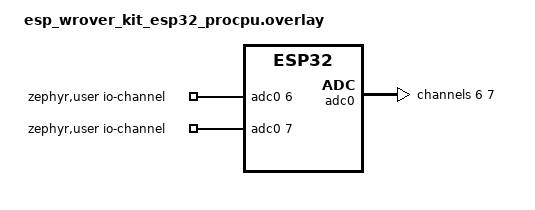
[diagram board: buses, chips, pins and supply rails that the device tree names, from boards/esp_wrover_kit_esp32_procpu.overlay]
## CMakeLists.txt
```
# SPDX-License-Identifier: Apache-2.0

cmake_minimum_required(VERSION 3.20.0)
find_package(Zephyr REQUIRED HINTS $ENV{ZEPHYR_BASE})
project(soil-monitor)

target_sources(app PRIVATE
    src/main.c
    src/wifi.c
)
```

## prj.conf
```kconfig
# ========================================
# CONFIGURAÇÕES DE HARDWARE E CONSOLE
# ========================================
CONFIG_GPIO=y
CONFIG_ADC=y
CONFIG_SERIAL=y
CONFIG_CONSOLE=y
CONFIG_UART_CONSOLE=y
CONFIG_PRINTK=y

# ========================================
# ZBUS (Barramento de Mensagens)
# ========================================
CONFIG_ZBUS=y

# ========================================
# REDE, WI-FI E NET_MGMT
# ========================================
CONFIG_NETWORKING=y
CONFIG_NET_IPV4=y
CONFIG_NET_TCP=y
CONFIG_NET_UDP=y
CONFIG_NET_SOCKETS=y
CONFIG_NET_MGMT=y
CONFIG_NET_MGMT_EVENT=y
CONFIG_WIFI=y
CONFIG_WIFI_ESP32=y
CONFIG_NET_L2_WIFI_MGMT=y
CONFIG_NET_DHCPV4=y

# ========================================
# ATIVAR A SHELL DO ZEPHYR (Novidade aqui)
# ========================================
CONFIG_SHELL=y
CONFIG_SHELL_STACK_SIZE=4096

# ========================================
# CONFIGURAÇÕES DE MEMÓRIA
# ========================================
CONFIG_MAIN_STACK_SIZE=4096
CONFIG_HEAP_MEM_POOL_SIZE=8192
```

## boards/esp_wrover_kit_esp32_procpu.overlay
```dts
/* SPDX-License-Identifier: Apache-2.0 */

/ {
	aliases {
		led0 = &red_led;
		led1 = &green_led;
		led2 = &blue_led;
	};

	zephyr,user {
		/* CORREÇÃO: Mapeia os canais indexados 0 e 1, respectivamente */
		io-channels = <&adc0 6>, <&adc0 7>;
	};
};

&adc0 {
	status = "okay";
	#address-cells = <1>;
	#size-cells = <0>;

	channel@6 {
		reg = <6>;
		zephyr,gain = "ADC_GAIN_1_4";
		zephyr,reference = "ADC_REF_INTERNAL";
		zephyr,acquisition-time = <ADC_ACQ_TIME_DEFAULT>;
		zephyr,resolution = <12>;
	};

	/* NOVO: Configuração para o segundo potenciômetro (GPIO 35) */
	channel@7 {
		reg = <7>;
		zephyr,gain = "ADC_GAIN_1_4";
		zephyr,reference = "ADC_REF_INTERNAL";
		zephyr,acquisition-time = <ADC_ACQ_TIME_DEFAULT>;
		zephyr,resolution = <12>;
	};
};
```

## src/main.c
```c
#include <zephyr/kernel.h>
#include <zephyr/drivers/gpio.h>
#include <zephyr/drivers/adc.h>
#include <zephyr/sys/printk.h>
#include <zephyr/zbus/zbus.h>
#include <zephyr/net/socket.h> /* Fornece as estruturas zsock_ e AF_INET */

#include "wifi.h"

/* ====================================================================
 * NOVO: Variável global para armazenar o estado da irrigação
 * ==================================================================== */
static volatile bool esta_irrigando = false;


/* NOVO: Guarda a última leitura do Pot1. Inicializado em 2000 (Úmido) 
   para segurança, evitando ligar o LED antes da primeira leitura do ADC */
   
static volatile uint16_t ultima_umidade = 2000; 


/* =========================================
 * MODIFICAÇÃO: Estrutura agora leva o estado
 * ========================================= */
struct pots_data {
    uint16_t pot1;
    uint16_t pot2;
    bool irrigando; /* NOVO CAMPO */
};

/* =========================================
 * DEFINIÇÃO DO ZBUS
 * ========================================= */
/* Inicializa o canal limpando também o novo campo booleano */
ZBUS_CHAN_DEFINE(adc_data_chan, struct pots_data, NULL, NULL, ZBUS_OBSERVERS_EMPTY, ZBUS_MSG_INIT(.pot1 = 0, .pot2 = 0, .irrigando = false));

ZBUS_SUBSCRIBER_DEFINE(http_subscriber, 4);
ZBUS_CHAN_ADD_OBS(adc_data_chan, http_subscriber, 3);

/* =========================================
 * CONFIGURAÇÕES DO SERVIDOR HTTP
 * ========================================= */
#define HTTP_SERVER_IP "192.168.0.5"
#define HTTP_SERVER_PORT 8080

/* =========================================
 * THREAD DO LED (Atualiza a variável global)
 * ========================================= */
#define SLEEP_TIME_ON_MS   10000
#define SLEEP_TIME_OFF_MS  10000
#define LED0_NODE DT_ALIAS(led0)
static const struct gpio_dt_spec led = GPIO_DT_SPEC_GET(LED0_NODE, gpios);

void led_thread_function(void) {
    if (!gpio_is_ready_dt(&led)) return;
    
    gpio_pin_configure_dt(&led, GPIO_OUTPUT_INACTIVE);

    while (1) {

        if (ultima_umidade < 1600){

            
            gpio_pin_set_dt(&led, 1);
            esta_irrigando = true;
            k_msleep(SLEEP_TIME_ON_MS);


            gpio_pin_set_dt(&led, 0);
            esta_irrigando = false;
            k_msleep(SLEEP_TIME_OFF_MS);

        }else{

            gpio_pin_set_dt(&led, 0);
            esta_irrigando = false;
            k_msleep(SLEEP_TIME_OFF_MS);
        }


    }

        
        


}
K_THREAD_DEFINE(led_thread_id, 512, led_thread_function, NULL, NULL, NULL, 7, 0, 0);



/* =========================================
 * THREAD DO HTTP (Envia o estado no JSON)
 * ========================================= */
static void send_http_post(struct pots_data data) {
    int sock;
    struct sockaddr_in server_addr;
    char payload[160]; /* Aumentado ligeiramente para a nova chave */
    char request[350];

    sock = zsock_socket(AF_INET, SOCK_STREAM, IPPROTO_TCP);
    if (sock < 0) return;

    server_addr.sin_family = AF_INET;
    server_addr.sin_port = htons(HTTP_SERVER_PORT);
    zsock_inet_pton(AF_INET, HTTP_SERVER_IP, &server_addr.sin_addr);

    if (zsock_connect(sock, (struct sockaddr *)&server_addr, sizeof(server_addr)) < 0) {
        printk("[HTTP] Falha ao conectar no servidor.\n");
        zsock_close(sock);
        return;
    }

    /* MODIFICAÇÃO: Inserção da chave "irrigando" passando true/false como string para o JSON */
    snprintf(payload, sizeof(payload), 
             "{\"potenciometro1\": %d, \"potenciometro2\": %d, \"irrigando\": %s}", 
             data.pot1, data.pot2, data.irrigando ? "true" : "false");
    
    snprintf(request, sizeof(request),
             "POST /api/dados HTTP/1.1\r\n"
             "Host: %s\r\n"
             "Content-Type: application/json\r\n"
             "Content-Length: %d\r\n"
             "Connection: close\r\n\r\n"
             "%s", HTTP_SERVER_IP, strlen(payload), payload);

    zsock_send(sock, request, strlen(request), 0);
    printk("[HTTP] ENVIADO -> Pot1: %d | Pot2: %d | Irrigando: %s\n", 
           data.pot1, data.pot2, data.irrigando ? "SIM" : "NAO");
    
    zsock_close(sock);
}

void http_client_thread(void) {
    const struct zbus_channel *chan;
    struct pots_data received_data;
    
    while (1) {
        if (zbus_sub_wait(&http_subscriber, &chan, K_FOREVER) == 0) {
            if (chan == &adc_data_chan) {
                zbus_chan_read(chan, &received_data, K_NO_WAIT);
                
                if (wifi_is_ready()) {
                    send_http_post(received_data);
                } else {
                    printk("[HTTP] Rede não pronta. Ignorando envio.\n");
                }
            }
        }
    }
}
K_THREAD_DEFINE(http_thread_id, 2048, http_client_thread, NULL, NULL, NULL, 5, 0, 0);


/* =========================================
 * THREAD PRINCIPAL (Adiciona o estado no ZBUS)
 * ========================================= */
static const struct adc_dt_spec pot1 = ADC_DT_SPEC_GET_BY_IDX(DT_PATH(zephyr_user), 0);
static const struct adc_dt_spec pot2 = ADC_DT_SPEC_GET_BY_IDX(DT_PATH(zephyr_user), 1);

int main(void) {
    int err1, err2;
    uint16_t buf_pot1;
    uint16_t buf_pot2;
    struct pots_data msg;

    wifi_init();

    struct adc_sequence seq1 = {
        .buffer = &buf_pot1,
        .buffer_size = sizeof(buf_pot1),
    };
    struct adc_sequence seq2 = {
        .buffer = &buf_pot2,
        .buffer_size = sizeof(buf_pot2),
    };

    if (!device_is_ready(pot1.dev) || adc_channel_setup_dt(&pot1) < 0 || adc_sequence_init_dt(&pot1, &seq1) < 0) {
        printk("Erro ao iniciar ADC no Potenciometro 1\n");
        return 0;
    }

    if (!device_is_ready(pot2.dev) || adc_channel_setup_dt(&pot2) < 0 || adc_sequence_init_dt(&pot2, &seq2) < 0) {
        printk("Erro ao iniciar ADC no Potenciometro 2\n");
        return 0;
    }

    while (1) {
        err1 = adc_read(pot1.dev, &seq1);
        err2 = adc_read(pot2.dev, &seq2);
        
        if (err1 == 0 && err2 == 0) {
            msg.pot1 = buf_pot1;
            msg.pot2 = buf_pot2;
            
            /* MODIFICAÇÃO: Captura o estado atualizado da irrigação antes de enviar */
            msg.irrigando = esta_irrigando;

            /* MODIFICAÇÃO: Atualiza a variável global que a Thread do LED consulta */
            ultima_umidade = buf_pot1;
            
            printk("[ADC] Lido Pot1: %d, Pot2: %d, Irrigando: %s | Publicando...\n", 
                   msg.pot1, msg.pot2, msg.irrigando ? "SIM" : "NAO");
                   
            zbus_chan_pub(&adc_data_chan, &msg, K_NO_WAIT);
        } else {
            printk("[ADC] Falha ao ler um dos sensores analógicos.\n");
        }
        
        k_msleep(3500); 
    }

    return 0;
}
```

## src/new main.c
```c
#include <zephyr/kernel.h>
#include <zephyr/drivers/gpio.h>
#include <zephyr/drivers/adc.h>
#include <zephyr/sys/printk.h>
#include <zephyr/zbus/zbus.h>
#include <zephyr/net/socket.h> /* Fornece as estruturas zsock_ e AF_INET */

#include "wifi.h"

/* =========================================
 * NOVO: Estrutura para unificar os sensores
 * ========================================= */
struct pots_data {
    uint16_t pot1;
    uint16_t pot2;
};

/* =========================================
 * DEFINIÇÃO DO ZBUS (Atualizado para struct)
 * ========================================= */
/* 1. Altera o tipo do canal de uint16_t para struct pots_data */
ZBUS_CHAN_DEFINE(adc_data_chan, struct pots_data, NULL, NULL, ZBUS_OBSERVERS_EMPTY, ZBUS_MSG_INIT(.pot1 = 0, .pot2 = 0));

/* 2. Define o Assinante (Subscriber) com um tamanho de fila */
ZBUS_SUBSCRIBER_DEFINE(http_subscriber, 4);

/* 3. Conecta o Assinante ao Canal estaticamente */
ZBUS_CHAN_ADD_OBS(adc_data_chan, http_subscriber, 3);

/* =========================================
 * CONFIGURAÇÕES DO SERVIDOR HTTP
 * ========================================= */
#define HTTP_SERVER_IP "192.168.0.5"
#define HTTP_SERVER_PORT 8080

/* =========================================
 * THREAD DO LED (Mantida estável)
 * ========================================= */
#define SLEEP_TIME_ON_MS   5000
#define SLEEP_TIME_OFF_MS  25000
#define LED0_NODE DT_ALIAS(led0)
static const struct gpio_dt_spec led = GPIO_DT_SPEC_GET(LED0_NODE, gpios);

void led_thread_function(void) {
    if (!gpio_is_ready_dt(&led)) return;
    
    gpio_pin_configure_dt(&led, GPIO_OUTPUT_INACTIVE);
    while (1) {
        gpio_pin_set_dt(&led, 1);
        k_msleep(SLEEP_TIME_ON_MS);
        gpio_pin_set_dt(&led, 0);
        k_msleep(SLEEP_TIME_OFF_MS);
    }
}
K_THREAD_DEFINE(led_thread_id, 512, led_thread_function, NULL, NULL, NULL, 7, 0, 0);


/* =========================================
 * THREAD DO HTTP (Modificada para 2 sensores)
 * ========================================= */
static void send_http_post(struct pots_data data) {
    int sock;
    struct sockaddr_in server_addr;
    char payload[128]; /* Aumentado para suportar o JSON maior */
    char request[320];

    sock = zsock_socket(AF_INET, SOCK_STREAM, IPPROTO_TCP);
    if (sock < 0) return;

    server_addr.sin_family = AF_INET;
    server_addr.sin_port = htons(HTTP_SERVER_PORT);
    zsock_inet_pton(AF_INET, HTTP_SERVER_IP, &server_addr.sin_addr);

    if (zsock_connect(sock, (struct sockaddr *)&server_addr, sizeof(server_addr)) < 0) {
        printk("[HTTP] Falha ao conectar no servidor.\n");
        zsock_close(sock);
        return;
    }

    /* MODIFICAÇÃO: Payload agora envia duas chaves no JSON */
    snprintf(payload, sizeof(payload), "{\"potenciometro1\": %d, \"potenciometro2\": %d}", data.pot1, data.pot2);
    
    snprintf(request, sizeof(request),
             "POST /api/dados HTTP/1.1\r\n"
             "Host: %s\r\n"
             "Content-Type: application/json\r\n"
             "Content-Length: %d\r\n"
             "Connection: close\r\n\r\n"
             "%s", HTTP_SERVER_IP, strlen(payload), payload);

    zsock_send(sock, request, strlen(request), 0);
    printk("[HTTP] DADOS ENVIADOS -> Pot1: %d | Pot2: %d\n", data.pot1, data.pot2);
    
    zsock_close(sock);
}

void http_client_thread(void) {
    const struct zbus_channel *chan;
    struct pots_data received_data; /* Tipo atualizado */
    
    while (1) {
        if (zbus_sub_wait(&http_subscriber, &chan, K_FOREVER) == 0) {
            if (chan == &adc_data_chan) {
                zbus_chan_read(chan, &received_data, K_NO_WAIT);
                
                if (wifi_is_ready()) {
                    send_http_post(received_data);
                } else {
                    printk("[HTTP] Rede não pronta. Ignorando envio.\n");
                }
            }
        }
    }
}
K_THREAD_DEFINE(http_thread_id, 2048, http_client_thread, NULL, NULL, NULL, 5, 0, 0);


/* =========================================
 * THREAD PRINCIPAL (Modificada para ler index 0 e 1)
 * ========================================= */
/* Obtém as especificações usando as macros indexadas do Devicetree (_BY_IDX) */
static const struct adc_dt_spec pot1 = ADC_DT_SPEC_GET_BY_IDX(DT_PATH(zephyr_user), 0);
static const struct adc_dt_spec pot2 = ADC_DT_SPEC_GET_BY_IDX(DT_PATH(zephyr_user), 1);

int main(void) {
    int err1, err2;
    uint16_t buf_pot1;
    uint16_t buf_pot2;
    struct pots_data msg;

    wifi_init();

    /* Configura sequências independentes para os buffers locais */
    struct adc_sequence seq1 = {
        .buffer = &buf_pot1,
        .buffer_size = sizeof(buf_pot1),
    };
    struct adc_sequence seq2 = {
        .buffer = &buf_pot2,
        .buffer_size = sizeof(buf_pot2),
    };

    /* Inicializa e valida o Potenciômetro 1 */
    if (!device_is_ready(pot1.dev) || adc_channel_setup_dt(&pot1) < 0 || adc_sequence_init_dt(&pot1, &seq1) < 0) {
        printk("Erro ao iniciar ADC no Potenciometro 1\n");
        return 0;
    }

    /* Inicializa e valida o Potenciômetro 2 */
    if (!device_is_ready(pot2.dev) || adc_channel_setup_dt(&pot2) < 0 || adc_sequence_init_dt(&pot2, &seq2) < 0) {
        printk("Erro ao iniciar ADC no Potenciometro 2\n");
        return 0;
    }

    while (1) {
        /* Realiza as duas leituras consecutivas */
        err1 = adc_read(pot1.dev, &seq1);
        err2 = adc_read(pot2.dev, &seq2);
        
        if (err1 == 0 && err2 == 0) {
            msg.pot1 = buf_pot1;
            msg.pot2 = buf_pot2;
            
            printk("[ADC] Lido Pot1: %d e Pot2: %d | Publicando struct no ZBUS...\n", msg.pot1, msg.pot2);
            zbus_chan_pub(&adc_data_chan, &msg, K_NO_WAIT);
        } else {
            printk("[ADC] Falha ao ler um dos sensores analógicos.\n");
        }
        
        k_msleep(10000); 
    }

    return 0;
}
```

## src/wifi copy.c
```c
#include "wifi.h"

#include <zephyr/kernel.h>
#include <zephyr/sys/printk.h>
#include <zephyr/net/net_if.h>
#include <zephyr/net/net_mgmt.h>
#include <zephyr/net/wifi_mgmt.h>

/* Configurações da Rede */
#define WIFI_SSID     "brisa-2789486"
#define WIFI_PASSWORD "ytokjmue"

static bool wifi_connected = false;
static bool wifi_got_ip = false;

static struct net_if *wifi_iface;

/* Estruturas independentes para não colidir máscaras de L2 (Wi-Fi) e L3 (IP) */
static struct net_mgmt_event_callback wifi_cb;
static struct net_mgmt_event_callback ipv4_cb;

/* Sincronização via Semáforos */
static struct k_sem wifi_connected_sem;
static struct k_sem wifi_got_ip_sem;

static void wifi_event_handler(struct net_mgmt_event_callback *cb,
                               uint64_t mgmt_event,
                               struct net_if *iface);


static void wifi_event_handler(struct net_mgmt_event_callback *cb,
                               uint64_t mgmt_event,
                               struct net_if *iface)
{
    switch (mgmt_event) {

    case NET_EVENT_WIFI_CONNECT_RESULT:
        printk("Wi-Fi conectado ao AP\n");
        wifi_connected = true;
        k_sem_give(&wifi_connected_sem);
        break;

    case NET_EVENT_WIFI_DISCONNECT_RESULT:
        printk("Wi-Fi desconectado\n");
        wifi_connected = false;
        break;

    case NET_EVENT_IPV4_ADDR_ADD:
        printk("IP obtido\n");
        wifi_got_ip = true;
        k_sem_give(&wifi_got_ip_sem);
        break;

    default:
        break;
    }
}

int wifi_init(void)
{
    printk("\n=====================================\n");
    printk(" Inicializando Wi-Fi\n");
    printk("=====================================\n");

    wifi_iface = net_if_get_default();

    if (!wifi_iface) {
        printk("Erro: interface não encontrada\n");
        return -1;
    }

    k_sem_init(&wifi_connected_sem, 0, 1);
    k_sem_init(&wifi_got_ip_sem, 0, 1);

    /* Registra os eventos da camada Wi-Fi (L2) */
    net_mgmt_init_event_callback(
        &wifi_cb,
        wifi_event_handler,
        NET_EVENT_WIFI_CONNECT_RESULT | NET_EVENT_WIFI_DISCONNECT_RESULT);
    net_mgmt_add_event_callback(&wifi_cb);

    /* Registra os eventos da camada IP (L3) separadamente */
    net_mgmt_init_event_callback(
        &ipv4_cb,
        wifi_event_handler,
        NET_EVENT_IPV4_ADDR_ADD);
    net_mgmt_add_event_callback(&ipv4_cb);

    printk("Wi-Fi pronto para conexão\n");

    return 0;
}


int wifi_connect(void)
{
    struct wifi_connect_req_params params;

    printk("\nConectando ao Wi-Fi...\n");

    memset(&params, 0, sizeof(params));

    params.ssid = (const uint8_t *)WIFI_SSID;
    params.ssid_length = strlen(WIFI_SSID);

    params.psk = WIFI_PASSWORD;
    params.psk_length = strlen(WIFI_PASSWORD);

    /* Mapeamento dos parâmetros validados no shell: -k 1 -b 2 -w 0 */
    params.security = WIFI_SECURITY_TYPE_PSK;   /* -k 1: Força WPA2-PSK */
    params.band = WIFI_FREQ_BAND_2_4_GHZ;       /* -b 2: Força operar apenas em 2.4GHz */
    params.mfp = WIFI_MFP_DISABLE;              /* -w 0: Desabilita MFP (Crucial para evitar Auth Error) */
    
    params.channel = WIFI_CHANNEL_ANY;

    int ret = net_mgmt(NET_REQUEST_WIFI_CONNECT,
                       wifi_iface,
                       &params,
                       sizeof(params));

    if (ret) {
        printk("Erro ao iniciar conexão: %d\n", ret);
        return ret;
    }

    printk("Aguardando conexão física...\n");

    /* Trava a thread até o callback liberar o semáforo (Timeout de 15s) */
    if (k_sem_take(&wifi_connected_sem, K_SECONDS(15)) != 0) {
        printk("ERRO: timeout conectando ao Wi-Fi\n");
        return -1;
    }

    printk("Aguardando DHCP (IP)...\n");

    /* Trava a thread aguardando o IP do roteador (Timeout de 15s) */
    if (k_sem_take(&wifi_got_ip_sem, K_SECONDS(15)) != 0) {
        printk("ERRO: timeout aguardando IP\n");
        return -1;
    }

    /* Resgata o IP diretamente da estrutura aninhada do Zephyr 4.x */
    if (wifi_iface->config.ip.ipv4) {
        uint8_t *ip = wifi_iface->config.ip.ipv4->unicast[0].ipv4.address.in_addr.s4_addr;
        
        printk("\nIP obtido: %d.%d.%d.%d\n", ip[0], ip[1], ip[2], ip[3]);
    } else {
        printk("ERRO: interface sem IP\n");
        return -1;
    }

    printk("Wi-Fi operante com sucesso!\n\n");

    return 0;
}
```

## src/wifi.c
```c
#include "wifi.h"
#include <zephyr/kernel.h>
#include <zephyr/net/net_if.h>
#include <zephyr/net/net_core.h>
#include <zephyr/net/net_mgmt.h>
#include <zephyr/net/wifi_mgmt.h>
#include <zephyr/shell/shell.h>
#include <zephyr/sys/printk.h>

static struct net_mgmt_event_callback dhcp_cb;
static bool network_ready = false;

/* ====================================================================
 * Callback acionado pelo net_mgmt quando o IP é recebido
 * ==================================================================== */
static void net_event_handler(struct net_mgmt_event_callback *cb, 
                              uint64_t mgmt_event, 
                              struct net_if *iface) 
{
    if (mgmt_event == NET_EVENT_IPV4_ADDR_ADD) {
        network_ready = true;
        printk("\n[WIFI] Rede conectada! IP obtido via DHCP.\n");
        
        if (iface->config.ip.ipv4 != NULL) {
            
            /* 1. Procura o IP do ESP32 */
            for (int i = 0; i < NET_IF_MAX_IPV4_ADDR; i++) {
                
                /* CORREÇÃO: Adicionado o acesso ao membro interno '.ipv4' */
                if (iface->config.ip.ipv4->unicast[i].ipv4.is_used) {
                    struct in_addr *ip_addr = &iface->config.ip.ipv4->unicast[i].ipv4.address.in_addr;
                    
                    /* CORREÇÃO: Transforma o ponteiro da estrutura num array de 4 bytes (Octetos do IP) */
                    uint8_t *ip = (uint8_t *)ip_addr;
                    printk("  -> IP do ESP32: %d.%d.%d.%d\n", ip[0], ip[1], ip[2], ip[3]);
                    
                    break;
                }
            }

            /* 2. Pega o endereço IP do Roteador (Gateway) */
            struct in_addr *gw_addr = &iface->config.ip.ipv4->gw;
            uint8_t *gw = (uint8_t *)gw_addr;
            printk("  -> IP do Roteador (Gateway): %d.%d.%d.%d\n\n", gw[0], gw[1], gw[2], gw[3]);
        }
    }
}

void wifi_init(void) 
{
    printk("[WIFI] Inicializando gerenciador de rede...\n");
    
    net_mgmt_init_event_callback(&dhcp_cb, net_event_handler, NET_EVENT_IPV4_ADDR_ADD);
    net_mgmt_add_event_callback(&dhcp_cb);
}

bool wifi_is_ready(void) 
{
    return network_ready;
}


/* ====================================================================
 * Comando Customizado da Shell para Conectar ao Wi-Fi
 * ==================================================================== */
static int cmd_conectar_wifi(const struct shell *sh, size_t argc, char **argv)
{
    struct net_if *iface = net_if_get_default();
    struct wifi_connect_req_params params = {0};

    if (argc < 2) {
        shell_error(sh, "Uso incorreto. Tente: conectar_wifi <SSID> [PALAVRA_PASSE]");
        return -EINVAL;
    }

    params.ssid = (const uint8_t *)argv[1];
    params.ssid_length = strlen(argv[1]);

    if (argc > 2) {
        params.psk = (const uint8_t *)argv[2];
        params.psk_length = strlen(argv[2]);
        params.security = WIFI_SECURITY_TYPE_PSK;
    } else {
        params.security = WIFI_SECURITY_TYPE_NONE;
    }

    params.channel = WIFI_CHANNEL_ANY;

    shell_print(sh, "Enviando solicitacao de conexao para o SSID: %s...", argv[1]);

    int err = net_mgmt(NET_REQUEST_WIFI_CONNECT, iface, &params, sizeof(struct wifi_connect_req_params));
    
    if (err) {
        shell_error(sh, "Erro ao repassar comando ao driver Wi-Fi: %d", err);
    } else {
        shell_print(sh, "Comando aceito. Aguarde a resposta DHCP...");
    }

    return err;
}

SHELL_CMD_REGISTER(conectar_wifi, NULL, "Conecta ao Wi-Fi: conectar_wifi <SSID> [SENHA]", cmd_conectar_wifi);
```

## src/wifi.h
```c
#ifndef WIFI_H
#define WIFI_H

#include <stdbool.h>

/**
 * @brief Inicializa os callbacks de gerenciamento de rede.
 */
void wifi_init(void);

/**
 * @brief Verifica se a placa obteve um endereço IP (DHCP concluído).
 * @return true se conectada e pronta, false caso contrário.
 */
bool wifi_is_ready(void);

#endif /* WIFI_H */
```
